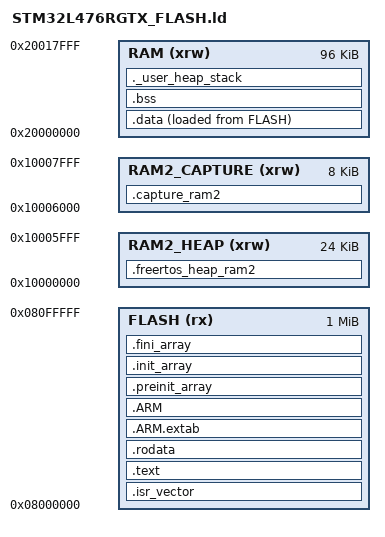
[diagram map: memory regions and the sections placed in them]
/*
******************************************************************************
**
** @file        : LinkerScript.ld
**
** @author      : Auto-generated by STM32CubeIDE
**
**  Abstract    : Linker script for NUCLEO-L476RG Board embedding STM32L476RGTx Device from stm32l4 series
**                      1024KBytes FLASH
**                      96KBytes RAM
**                      32KBytes RAM2
**
**                Set heap size, stack size and stack location according
**                to application requirements.
**
**                Set memory bank area and size if external memory is used
**
**  Target      : STMicroelectronics STM32
**
**  Distribution: The file is distributed as is, without any warranty
**                of any kind.
**
******************************************************************************
** @attention
**
** Copyright (c) 2026 STMicroelectronics.
** All rights reserved.
**
** This software is licensed under terms that can be found in the LICENSE file
** in the root directory of this software component.
** If no LICENSE file comes with this software, it is provided AS-IS.
**
******************************************************************************
*/

/* Entry Point */
ENTRY(Reset_Handler)

/* Highest address of the user mode stack */
_estack = ORIGIN(RAM) + LENGTH(RAM); /* end of "RAM" Ram type memory */

_Min_Heap_Size = 0x800; /* 2KB Newlib heap reservation; FreeRTOS heap_4 has its own 32KB ucHeap */
_Min_Stack_Size = 0x1000; /* required amount of stack */

/* Memories definition */
MEMORY
{
  RAM    (xrw)    : ORIGIN = 0x20000000,   LENGTH = 96K
  /* Separate hard SRAM2 banks: linker rejects oversubscription of either region. */
  RAM2_HEAP    (xrw) : ORIGIN = 0x10000000, LENGTH = 24K
  RAM2_CAPTURE (xrw) : ORIGIN = 0x10006000, LENGTH = 8K
  FLASH    (rx)    : ORIGIN = 0x8000000,   LENGTH = 1024K
}

/* Sections */
SECTIONS
{

  /* The startup code into "FLASH" Rom type memory */
  .isr_vector :
  {
    . = ALIGN(4);
    KEEP(*(.isr_vector)) /* Startup code */
    . = ALIGN(4);
  } >FLASH

  /* The program code and other data into "FLASH" Rom type memory */
  .text :
  {
    . = ALIGN(4);
    *(.text)           /* .text sections (code) */
    *(.text*)          /* .text* sections (code) */
    *(.glue_7)         /* glue arm to thumb code */
    *(.glue_7t)        /* glue thumb to arm code */
    *(.eh_frame)

    KEEP (*(.init))
    KEEP (*(.fini))

    . = ALIGN(4);
    _etext = .;        /* define a global symbols at end of code */
  } >FLASH

  /* Constant data into "FLASH" Rom type memory */
  .rodata :
  {
    . = ALIGN(4);
    *(.rodata)         /* .rodata sections (constants, strings, etc.) */
    *(.rodata*)        /* .rodata* sections (constants, strings, etc.) */
    . = ALIGN(4);
  } >FLASH

  .ARM.extab (READONLY) : /* The "READONLY" keyword is only supported in GCC11 and later, remove it if using GCC10 or earlier. */
  {
    . = ALIGN(4);
    *(.ARM.extab* .gnu.linkonce.armextab.*)
    . = ALIGN(4);
  } >FLASH

  .ARM (READONLY) : /* The "READONLY" keyword is only supported in GCC11 and later, remove it if using GCC10 or earlier. */
  {
    . = ALIGN(4);
    __exidx_start = .;
    *(.ARM.exidx*)
    __exidx_end = .;
    . = ALIGN(4);
  } >FLASH

  .preinit_array (READONLY) : /* The "READONLY" keyword is only supported in GCC11 and later, remove it if using GCC10 or earlier. */
  {
    . = ALIGN(4);
    PROVIDE_HIDDEN (__preinit_array_start = .);
    KEEP (*(.preinit_array*))
    PROVIDE_HIDDEN (__preinit_array_end = .);
    . = ALIGN(4);
  } >FLASH

  .init_array (READONLY) : /* The "READONLY" keyword is only supported in GCC11 and later, remove it if using GCC10 or earlier. */
  {
    . = ALIGN(4);
    PROVIDE_HIDDEN (__init_array_start = .);
    KEEP (*(SORT(.init_array.*)))
    KEEP (*(.init_array*))
    PROVIDE_HIDDEN (__init_array_end = .);
    . = ALIGN(4);
  } >FLASH

  .fini_array (READONLY) : /* The "READONLY" keyword is only supported in GCC11 and later, remove it if using GCC10 or earlier. */
  {
    . = ALIGN(4);
    PROVIDE_HIDDEN (__fini_array_start = .);
    KEEP (*(SORT(.fini_array.*)))
    KEEP (*(.fini_array*))
    PROVIDE_HIDDEN (__fini_array_end = .);
    . = ALIGN(4);
  } >FLASH

  /* Used by the startup to initialize data */
  _sidata = LOADADDR(.data);

  /* Initialized data sections into "RAM" Ram type memory */
  .data :
  {
    . = ALIGN(4);
    _sdata = .;        /* create a global symbol at data start */
    *(.data)           /* .data sections */
    *(.data*)          /* .data* sections */
    *(.RamFunc)        /* .RamFunc sections */
    *(.RamFunc*)       /* .RamFunc* sections */

    . = ALIGN(4);
    _edata = .;        /* define a global symbol at data end */

  } >RAM AT> FLASH

  /* Uninitialized data section into "RAM" Ram type memory */
  . = ALIGN(4);
  .bss :
  {
    /* This is used by the startup in order to initialize the .bss section */
    _sbss = .;         /* define a global symbol at bss start */
    __bss_start__ = _sbss;
    *(.bss)
    *(.bss*)
    *(COMMON)

    . = ALIGN(4);
    _ebss = .;         /* define a global symbol at bss end */
    __bss_end__ = _ebss;
  } >RAM

  /* R26.7: a 24 KiB FreeRTOS heap and separate 8 KiB recorder are CPU-owned SRAM2, NOT DMA RAM.
   * NOLOAD prevents adding 32 KiB of meaningless zero bytes to the flash image.
   * Reset_Handler explicitly zeros the section; SRAM1 DMA audio buffers remain
   * in normal .bss and are initialized through the standard startup loop.
   */
  .freertos_heap_ram2 (NOLOAD) :
  {
    . = ALIGN(8);
    _sram2_heap_start = .;
    KEEP(*(.freertos_heap_ram2))
    . = ALIGN(8);
    _sram2_heap_end = .;
  } >RAM2_HEAP

  /* Reserved scratch: raw capture and pre-DSP listening recorder are mutually
   * exclusive. This section is deliberately separate from the RTOS heap.
   * Reserve it explicitly, preventing accidental heap/recorder aliasing.
   */
  .capture_ram2 (NOLOAD) :
  {
    . = ALIGN(8);
    _capture_ram2_start = .;
    . = . + 8192;
    _capture_ram2_end = .;
  } >RAM2_CAPTURE

  /* ROM/RAM bounds are enforced by dedicated MEMORY regions rather than
   * a GNU-ld SIZEOF assertion that can be evaluated before garbage collection
   * and was failing on the user's GNU ARM 13.3 linker. The C object ucHeap has
   * configTOTAL_HEAP_SIZE bytes, and the entire capture section is reserved.
   * There is no virtual alias and neither DMA data nor the initial stack
   * are placed in SRAM2. */
  ASSERT(_sram2_heap_end <= ORIGIN(RAM2_HEAP) + LENGTH(RAM2_HEAP), "FreeRTOS SRAM2 heap overflow")
  ASSERT(_capture_ram2_end <= ORIGIN(RAM2_CAPTURE) + LENGTH(RAM2_CAPTURE), "SRAM2 capture overflow")

  /* User_heap_stack section, used to check that there is enough "RAM" Ram  type memory left */
  ._user_heap_stack :
  {
    . = ALIGN(8);
    PROVIDE ( end = . );
    PROVIDE ( _end = . );
    . = . + _Min_Heap_Size;
    . = . + _Min_Stack_Size;
    . = ALIGN(8);
  } >RAM

  /* Remove information from the compiler libraries */
  /DISCARD/ :
  {
    libc.a ( * )
    libm.a ( * )
    libgcc.a ( * )
  }

  .ARM.attributes 0 : { *(.ARM.attributes) }
}
